# STM32H743 register map
File version: 2.4
CPU: CM7 r0p1, little endian, MPU, FPU, 4 interrupt priority bits
Registers are 32-bit, read-write, reset 0x0 unless marked. A register's access mark holds for its fields unless they carry their own. Offsets are from the block's base; [hi:lo] are bit positions; {n}, {i} and the like mark numbered series.

## SDMMC1
Base 0x52007000
Same registers: SDMMC2 0x48022400
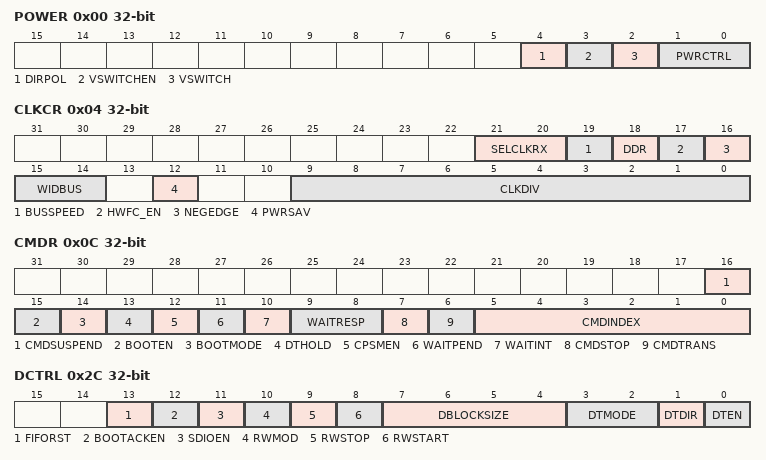
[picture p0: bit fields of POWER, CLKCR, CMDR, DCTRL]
0x00 POWER — SDMMC 电源控制寄存器
  [4] DIRPOL — 数据和命令方向信号极性选择。此位仅可在 SDMMC 处于断电状态（PWRCTRL = 00）时写入。
  [3] VSWITCHEN — 电压切换过程使能。此位仅可在 CPSM 禁用（CPSMEN = 0）时由固件写入。用于在电压切换命令响应后停止 SDMMC_CK：
  [2] VSWITCH — 电压切换序列启动。此位用于启动电压切换序列中的时序关键段：
  [1:0] PWRCTRL — SDMMC 状态控制位。这些位仅可在 SDMMC 未处于上电状态（PWRCTRL ≠ 11）时写入。用于定义 SDMMC 信号的功能状态：任何后续写入将被忽略，PWRCTRL 值将保持 11。
0x04 CLKCR — SDMMC_CLKCR 寄存器控制 SDMMC_CK 输出时钟、SDMMC_RX_CLK 接收时钟和总线宽度。
  [21:20] SELCLKRX — 接收时钟选择。这些位仅可在 CPSM 和 DPSM 均未激活（CPSMACT = 0 且 DPSMACT = 0）时写入。
  [19] BUSSPEED — 总线速度模式选择，可选 DS、HS、SDR12、SDR25、SDR50、DDR50、SDR104。此位仅可在 CPSM 和 DPSM 均未激活（CPSMACT = 0 且 DPSMACT = 0）时写入。
  [18] DDR — 数据速率信令选择。此位仅可在 CPSM 和 DPSM 均未激活（CPSMACT = 0 且 DPSMACT = 0）时写入。DDR 速率仅可在 4 位或 8 位宽总线模式（WIDBUS > 00）下选择。当 WIDBUS = 00（1 位宽总线）时，DDR = 1 无效。DDR 速率仅可在时钟分频 > 1（CLKDIV > 0）时选择。
  [17] HWFC_EN — 硬件流控使能。此位仅可在 CPSM 和 DPSM 均未激活（CPSMACT = 0 且 DPSMACT = 0）时写入。当硬件流控使能后，TXFIFOE 和 RXFIFOF 标志的含义将发生改变，请参阅第 56.8.11 节中的 SDMMC 状态寄存器定义。
  [16] NEGEDGE — SDMMC_CK 数据和命令去相位选择位。此位仅可在 CPSM 和 DPSM 均未激活（CPSMACT = 0 且 DPSMACT = 0）时写入。当时钟分频 = 1（CLKDIV = 0）时，此位无效。数据和命令在 SDMMC_CK 下降沿变化。当时钟分频 > 1（CLKDIV > 0）且 DDR = 0 时：- SDMMC_CK 边沿出现在 SDMMCCLK 上升沿。当时钟分频 > 1（CLKDIV > 0）且 DDR = 1 时：- 数据在 SDMMC_CK 边沿之后的 SDMMCCLK 下降沿变化。- SDMMC_CK 边沿出现在 SDMMCCLK 上升沿。- 数据在 SDMMC_CK 边沿之后的 SDMMC_CK 下降沿变化。- SDMMC_CK 边沿出现在 SDMMCCLK 上升沿。
  [15:14] WIDBUS — 宽总线模式使能位。此位仅可在 CPSM 和 DPSM 均未激活（CPSMACT = 0 且 DPSMACT = 0）时写入。
  [12] PWRSAV — 省电配置位。此位仅可在 CPSM 和 DPSM 均未激活（CPSMACT = 0 且 DPSMACT = 0）时写入。为节省功耗，可通过设置 PWRSAV 在总线空闲时禁用 SDMMC_CK 时钟输出：
  [9:0] CLKDIV — 时钟分频因子。此位仅可在 CPSM 和 DPSM 均未激活（CPSMACT = 0 且 DPSMACT = 0）时写入。此字段定义输入时钟（SDMMCCLK）与输出时钟（SDMMC_CK）之间的分频比：SDMMC_CK 频率 = SDMMCCLK / [2 × CLKDIV]。0xx：等等.. xxx：等等..
0x08 ARGR — SDMMC_ARGR 寄存器包含一个 32 位命令参数，作为命令消息的一部分发送给卡。
  [31:0] CMDARG — 命令参数。这些位仅可在 CPSM 禁用（CPSMEN = 0）时由固件写入。作为命令消息的一部分发送给卡的命令参数。如果命令包含参数，则必须在向命令寄存器写入命令之前将其加载到此寄存器中。
0x0C CMDR — SDMMC_CMDR 寄存器包含命令索引和命令类型位。命令索引作为命令消息的一部分发送给卡。命令类型位控制命令路径状态机（CPSM）。
  [16] CMDSUSPEND — CPSM 将该命令视为挂起或恢复命令，并发出中断周期开始/结束信号。此位仅可在 CPSM 禁用（CPSMEN = 0）时由固件写入。CMDSUSPEND = 1 且 CMDTRANS = 0：挂起命令，当响应位 BS = 0 时启动中断周期。CMDSUSPEND = 1 且 CMDTRANS = 1：带数据的恢复命令，当响应位 DF = 1 时结束中断周期。
  [15] BOOTEN — 使能引导模式过程。
  [14] BOOTMODE — 选择要使用的引导模式过程。此位仅可在 CPSM 禁用（CPSMEN = 0）时由固件写入。
  [13] DTHOLD — 在 DPSM 中暂停新数据块的发送和接收。如果此位置位，DPSM 将不会从 Wait_S 状态转移到 Send 状态，也不会从 Wait_R 状态转移到 Receive 状态。
  [12] CPSMEN — 命令路径状态机（CPSM）使能位。此位由固件写 1，当 CPSM 进入空闲状态时由硬件清零。如果此位置位，则 CPSM 使能。当 DTEN = 1 时，不会传输任何命令，也不会启动引导过程，CPSMEN 被清零为 0。
  [11] WAITPEND — CPSM 等待来自 DPSM 的数据传输结束信号（CmdPend 内部信号）。此位置位时，CPSM 在开始发送命令之前等待数据传输结束触发。WAITPEND 仅在 DTMODE = MMC 流数据传输、WIDBUS = 1 位宽总线模式、DPSMACT = 1 且 DTDIR = 主机到卡时生效。
  [10] WAITINT — CPSM 等待中断请求。如果此位置位，则 CPSM 禁用命令超时并等待卡中断请求（响应）。如果在 CPSM 等待状态下清除此位，将导致中断模式中止。
  [9:8] WAITRESP — 等待响应位。此位仅可在 CPSM 禁用（CPSMEN = 0）时由固件写入。用于配置 CPSM 是否等待响应，以及如需等待，等待何种类型的响应。
  [7] CMDSTOP — CPSM 将该命令视为停止传输命令，并向 DPSM 发送 Abort 信号。此位仅可在 CPSM 禁用（CPSMEN = 0）时由固件写入。如果此位置位，则 CPSM 在发送命令时向 DPSM 发出 Abort 信号。
  [6] CMDTRANS — CPSM 将该命令视为数据传输命令，停止中断周期，并向 DPSM 发送 DataEnable 信号。此位仅可在 CPSM 禁用（CPSMEN = 0）时由固件写入。如果此位置位，则 CPSM 在发送命令时发出中断周期结束信号，并向 DPSM 发出 DataEnable 信号。
  [5:0] CMDINDEX — 命令索引。此位仅可在 CPSM 禁用（CPSMEN = 0）时由固件写入。命令索引作为命令消息的一部分发送给卡。
0x10 RESPCMDR ro reset 0xA3C5DD01 — SDMMC 命令响应寄存器
  [5:0] RESPCMD — 响应命令索引
0x14 RESP1R ro — SDMMC_RESP1/2/3/4R 寄存器包含卡的状态信息，该状态是接收到的响应的一部分。
  [31:0] CARDSTATUS1 — 参见表 432。
{0x10+4i} RESP{i}R ro (i=2..4) — SDMMC_RESP1/2/3/4R 寄存器包含卡的状态信息，该状态是接收到的响应的一部分。
  [31:0] CARDSTATUS{i} — 参见表 404。
0x24 DTIMER — SDMMC_DTIMER 寄存器包含数据超时周期，以卡总线时钟周期为单位。一个计数器从 SDMMC_DTIMER 寄存器加载值，并在数据路径状态机（DPSM）进入 Wait_R 或 Busy 状态时开始递减。如果在 DPSM 处于上述任一状态时定时器计到 0，则超时状态标志置位。
  [31:0] DATATIME — 数据和 R1b 忙超时周期。此位仅可在 CPSM 和 DPSM 均未激活（CPSMACT = 0 且 DPSMACT = 0）时写入。以卡总线时钟周期为单位表示的数据和 R1b 忙超时周期。
0x28 DLENR — SDMMC_DLENR 寄存器包含要传输的数据字节数。该值在数据传输开始时加载到数据计数器中。
  [24:0] DATALENGTH — 数据长度值。此寄存器仅可在 DPSM 未激活（DPSMACT = 0）时由固件写入。要传输的数据字节数。当 DDR = 1 时，DATALENGTH 被截断为 2 的倍数（最后一个奇数字节不被传输）。当 DATALENGTH = 0 时，不传输任何数据；当 CPSMEN 和 CMDTRANS = 1 请求时，也不传输任何命令，DTEN 和 CPSMEN 被清零为 0。
0x2C DCTRL — SDMMC_DCTRL 寄存器控制数据路径状态机（DPSM）。
  [13] FIFORST — FIFO 复位，将清空所有剩余数据。此位仅可在 IDMAEN = 0 且 DPSM 激活（DPSMACT = 1）时由固件写入。此位仅在发生传输错误或传输暂停时生效。
  [12] BOOTACKEN — 使能引导确认的接收。此位仅可在 DPSM 未激活（DPSMACT = 0）时由固件写入。
  [11] SDIOEN — SD I/O 中断使能功能。此位仅可在 DPSM 未激活（DPSMACT = 0）时由固件写入。如果此位置位，则 DPSM 使能 SD I/O 卡特定的中断操作。
  [10] RWMOD — 读等待模式。此位仅可在 DPSM 未激活（DPSMACT = 0）时由固件写入。
  [9] RWSTOP — 读等待停止。此位由固件写入，当 DPSM 从 READ_WAIT 状态转移到 WAIT_R 或 IDLE 状态时由硬件自动清零。
  [8] RWSTART — 读等待启动。如果此位置位，读等待操作启动。
  [7:4] DBLOCKSIZE — 数据块大小。此位仅可在 DPSM 未激活（DPSMACT = 0）时由固件写入。定义选择块数据传输模式时的数据块长度：当 DATALENGTH 不是 DBLOCKSIZE 的倍数时，传输的数据在 DBLOCKSIZE 的倍数处截断（任何剩余数据将不被传输）。当 DDR = 1 时，不得使用 DBLOCKSIZE = 0000（不会传输任何数据）。
  [3:2] DTMODE — 数据传输模式选择。此位仅可在 DPSM 未激活（DPSMACT = 0）时由固件写入。
  [1] DTDIR — 数据传输方向选择。此位仅可在 DPSM 未激活（DPSMACT = 0）时由固件写入。
  [0] DTEN — 数据传输使能位。此位仅可在 DPSM 未激活（DPSMACT = 0）时由固件写入。数据传输完成时由硬件清零。此位仅应在不使用关联数据传输命令时用于传输数据，即不应与 SD 或 eMMC 卡一起使用。
0x30 DCNTR ro — 当 DPSM 从空闲状态转移到 Wait_R 或 Wait_S 状态时，SDMMC_DCNTR 寄存器从数据长度寄存器（参见 SDMMC_DLENR）加载值。随着数据传输，计数器递减该值直到达到 0。然后 DPSM 转移到空闲状态，当没有错误发生时，数据状态结束标志（DATAEND）置位。
  [24:0] DATACOUNT — 数据计数值。读取时，返回剩余待传输的数据字节数。写入无效。
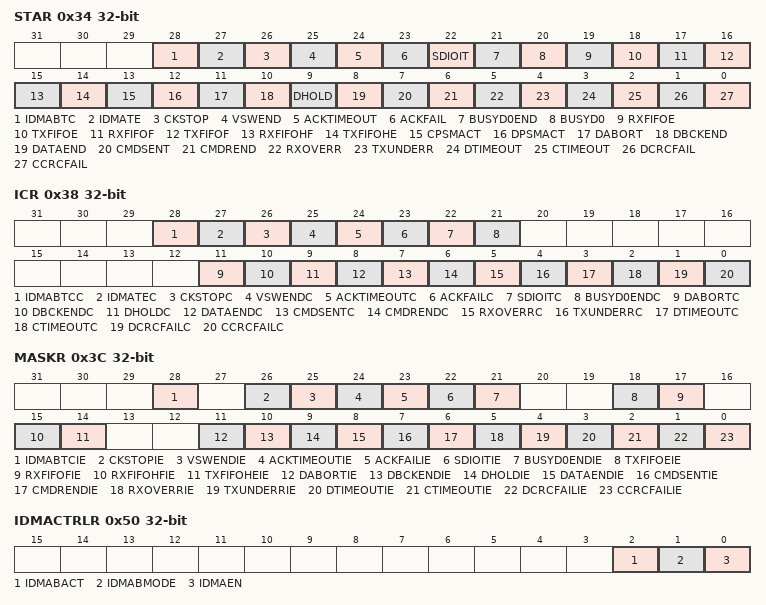
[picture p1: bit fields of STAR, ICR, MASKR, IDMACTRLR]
0x34 STAR ro — SDMMC_STAR 寄存器为只读寄存器。包含两种类型的标志：静态标志（位 [29, 21, 11:0]）：这些位保持有效状态，直到通过写入 SDMMC 中断清零寄存器（参见 SDMMC_ICR）将其清零。动态标志（位 [20:12]）：这些位根据底层逻辑的状态改变状态（例如，FIFO 满和空标志在数据写入 FIFO 时置位和清零）。
  [28] IDMABTC — IDMA 缓冲区传输完成。通过写入 SDMMC_ICR 中对应的中断清零位来清除此中断标志。
  [27] IDMATE — IDMA 传输错误。通过写入 SDMMC_ICR 中对应的中断清零位来清除此中断标志。
  [26] CKSTOP — SDMMC_CK 在电压切换过程中停止。通过写入 SDMMC_ICR 中对应的中断清零位来清除此中断标志。
  [25] VSWEND — 电压切换时序关键段完成。通过写入 SDMMC_ICR 中对应的中断清零位来清除此中断标志。
  [24] ACKTIMEOUT — 引导确认超时。通过写入 SDMMC_ICR 中对应的中断清零位来清除此中断标志。
  [23] ACKFAIL — 收到引导确认（引导确认校验失败）。通过写入 SDMMC_ICR 中对应的中断清零位来清除此中断标志。
  [22] SDIOIT — 收到 SDIO 中断。通过写入 SDMMC_ICR 中对应的中断清零位来清除此中断标志。
  [21] BUSYD0END — 检测到 CMD 响应后的 SDMMC_D0 忙结束。这仅指示 CMD 响应后的忙结束。此位不指示由数据传输引起的忙状态。通过写入 SDMMC_ICR 中对应的中断清零位来清除此中断标志。
  [20] BUSYD0 — SDMMC_D0 线（Busy）的反相值，在 CMD 响应结束时采样一次，并在 CMD 响应后 2 个 SDMMC_CK 周期再次采样。当 SDMMC_D0 线从忙变为不忙时，此位复位为不忙。此位不指示由数据传输引起的忙状态。此标志仅为硬件状态标志，不产生中断。
  [19] RXFIFOE — 接收 FIFO 空。此标志仅为硬件状态标志，不产生中断。当 FIFO 有一个位置变为满时，此位清零。
  [18] TXFIFOE — 发送 FIFO 空。当 FIFO 有一个位置变为满时，此位清零。
  [17] RXFIFOF — 接收 FIFO 满。当 FIFO 有一个位置变为空时，此位清零。
  [16] TXFIFOF — 发送 FIFO 满。此标志仅为硬件状态标志，不产生中断。当 FIFO 有一个位置变为空时，此位清零。
  [15] RXFIFOHF — 接收 FIFO 半满。FIFO 中至少有总容量一半的字数。当 FIFO 变为半空 + 1 时，此位清零。
  [14] TXFIFOHE — 发送 FIFO 半空。至少有一半容量的字可写入 FIFO。当 FIFO 变为半满 + 1 时，此位清零。
  [13] CPSMACT — 命令路径状态机激活，即不在空闲状态。此标志仅为硬件状态标志，不产生中断。
  [12] DPSMACT — 数据路径状态机激活，即不在空闲状态。此标志仅为硬件状态标志，不产生中断。
  [11] DABORT — 数据传输被 CMD12 中止。通过写入 SDMMC_ICR 中对应的中断清零位来清除此中断标志。
  [10] DBCKEND — 数据块已发送/接收（CRC 校验通过），且 DPSM 转移到 READWAIT 状态。通过写入 SDMMC_ICR 中对应的中断清零位来清除此中断标志。
  [9] DHOLD — 数据传输暂停。通过写入 SDMMC_ICR 中对应的中断清零位来清除此中断标志。
  [8] DATAEND — 数据传输正确结束（数据计数器 DATACOUNT 为零且未发生错误）。通过写入 SDMMC_ICR 中对应的中断清零位来清除此中断标志。
  [7] CMDSENT — 命令已发送（无需响应）。通过写入 SDMMC_ICR 中对应的中断清零位来清除此中断标志。
  [6] CMDREND — 收到命令响应（CRC 校验通过或无 CRC）。通过写入 SDMMC_ICR 中对应的中断清零位来清除此中断标志。
  [5] RXOVERR — 接收 FIFO 溢出错误或 IDMA 写传输错误。通过写入 SDMMC_ICR 中对应的中断清零位来清除此中断标志。
  [4] TXUNDERR — 发送 FIFO 欠载错误或 IDMA 读传输错误。通过写入 SDMMC_ICR 中对应的中断清零位来清除此中断标志。
  [3] DTIMEOUT — 数据超时。通过写入 SDMMC_ICR 中对应的中断清零位来清除此中断标志。
  [2] CTIMEOUT — 命令响应超时。通过写入 SDMMC_ICR 中对应的中断清零位来清除此中断标志。命令超时周期固定为 64 个 SDMMC_CK 时钟周期。
  [1] DCRCFAIL — 数据块已发送/接收（CRC 校验失败）。通过写入 SDMMC_ICR 中对应的中断清零位来清除此中断标志。
  [0] CCRCFAIL — 收到命令响应（CRC 校验失败）。通过写入 SDMMC_ICR 中对应的中断清零位来清除此中断标志。
0x38 ICR — SDMMC_ICR 寄存器为只写寄存器。将某位写 1 可清零 SDMMC_STAR 状态寄存器中对应的位。
  [28] IDMABTCC — IDMA 缓冲区传输完成清零位。由软件置位以清零 IDMABTC 标志。
  [27] IDMATEC — IDMA 传输错误清零位。由软件置位以清零 IDMATE 标志。
  [26] CKSTOPC — CKSTOP 标志清零位。由软件置位以清零 CKSTOP 标志。
  [25] VSWENDC — VSWEND 标志清零位。由软件置位以清零 VSWEND 标志。
  [24] ACKTIMEOUTC — ACKTIMEOUT 标志清零位。由软件置位以清零 ACKTIMEOUT 标志。
  [23] ACKFAILC — ACKFAIL 标志清零位。由软件置位以清零 ACKFAIL 标志。
  [22] SDIOITC — SDIOIT 标志清零位。由软件置位以清零 SDIOIT 标志。
  [21] BUSYD0ENDC — BUSYD0END 标志清零位。由软件置位以清零 BUSYD0END 标志。
  [11] DABORTC — DABORT 标志清零位。由软件置位以清零 DABORT 标志。
  [10] DBCKENDC — DBCKEND 标志清零位。由软件置位以清零 DBCKEND 标志。
  [9] DHOLDC — DHOLD 标志清零位。由软件置位以清零 DHOLD 标志。
  [8] DATAENDC — DATAEND 标志清零位。由软件置位以清零 DATAEND 标志。
  [7] CMDSENTC — CMDSENT 标志清零位。由软件置位以清零 CMDSENT 标志。
  [6] CMDRENDC — CMDREND 标志清零位。由软件置位以清零 CMDREND 标志。
  [5] RXOVERRC — RXOVERR 标志清零位。由软件置位以清零 RXOVERR 标志。
  [4] TXUNDERRC — TXUNDERR 标志清零位。由软件置位以清零 TXUNDERR 标志。
  [3] DTIMEOUTC — DTIMEOUT 标志清零位。由软件置位以清零 DTIMEOUT 标志。
  [2] CTIMEOUTC — CTIMEOUT 标志清零位。由软件置位以清零 CTIMEOUT 标志。
  [1] DCRCFAILC — DCRCFAIL 标志清零位。由软件置位以清零 DCRCFAIL 标志。
  [0] CCRCFAILC — CCRCFAIL 标志清零位。由软件置位以清零 CCRCFAIL 标志。
0x3C MASKR — 中断屏蔽寄存器通过将对应位置 1 来确定哪些状态标志产生中断请求。
  [28] IDMABTCIE — IDMA 缓冲区传输完成中断使能。由软件置位/清零以使能/禁用 IDMA 完成传输某个内存缓冲区的全部数据时产生的中断。
  [26] CKSTOPIE — 电压切换时钟停止中断使能。由软件置位/清零以使能/禁用由电压切换时钟停止引起的中断。
  [25] VSWENDIE — 电压切换时序关键段完成中断使能。由软件置位/清零以使能/禁用电压切换时序关键段完成时产生的中断。
  [24] ACKTIMEOUTIE — 确认超时中断使能。由软件置位/清零以使能/禁用由确认超时引起的中断。
  [23] ACKFAILIE — 确认失败中断使能。由软件置位/清零以使能/禁用由确认失败引起的中断。
  [22] SDIOITIE — SDIO 模式中断接收中断使能。由软件置位/清零以使能/禁用接收到 SDIO 模式中断时产生的中断。
  [21] BUSYD0ENDIE — BUSYD0END 中断使能。由软件置位/清零以使能/禁用在 CMD 响应后 SDMMC_D0 信号从忙变为不忙时产生的中断。
  [18] TXFIFOEIE — 发送 FIFO 空中断使能。由软件置位/清零以使能/禁用由发送 FIFO 空引起的中断。
  [17] RXFIFOFIE — 接收 FIFO 满中断使能。由软件置位/清零以使能/禁用由接收 FIFO 满引起的中断。
  [15] RXFIFOHFIE — 接收 FIFO 半满中断使能。由软件置位/清零以使能/禁用由接收 FIFO 半满引起的中断。
  [14] TXFIFOHEIE — 发送 FIFO 半空中断使能。由软件置位/清零以使能/禁用由发送 FIFO 半空引起的中断。
  [11] DABORTIE — 数据传输中止中断使能。由软件置位/清零以使能/禁用由数据传输被中止引起的中断。
  [10] DBCKENDIE — 数据块结束中断使能。由软件置位/清零以使能/禁用由数据块结束引起的中断。
  [9] DHOLDIE — 数据暂停中断使能。由软件置位/清零以使能/禁用在 DPSM Wait_S 状态下暂停发送新数据时产生的中断。
  [8] DATAENDIE — 数据结束中断使能。由软件置位/清零以使能/禁用由数据结束引起的中断。
  [7] CMDSENTIE — 命令发送中断使能。由软件置位/清零以使能/禁用由命令发送引起的中断。
  [6] CMDRENDIE — 命令响应接收中断使能。由软件置位/清零以使能/禁用由收到命令响应引起的中断。
  [5] RXOVERRIE — 接收 FIFO 溢出错误中断使能。由软件置位/清零以使能/禁用由接收 FIFO 溢出错误引起的中断。
  [4] TXUNDERRIE — 发送 FIFO 欠载错误中断使能。由软件置位/清零以使能/禁用由发送 FIFO 欠载错误引起的中断。
  [3] DTIMEOUTIE — 数据超时中断使能。由软件置位/清零以使能/禁用由数据超时引起的中断。
  [2] CTIMEOUTIE — 命令超时中断使能。由软件置位/清零以使能/禁用由命令超时引起的中断。
  [1] DCRCFAILIE — 数据 CRC 校验失败中断使能。由软件置位/清零以使能/禁用由数据 CRC 校验失败引起的中断。
  [0] CCRCFAILIE — 命令 CRC 校验失败中断使能。由软件置位/清零以使能/禁用由命令 CRC 校验失败引起的中断。
0x40 ACKTIMER — SDMMC_ACKTIMER 寄存器包含确认超时周期，以 SDMMC_CK 总线时钟周期为单位。一个计数器从 SDMMC_ACKTIMER 寄存器加载值，并在数据路径状态机（DPSM）进入 Wait_Ack 状态时开始递减。如果在 DPSM 处于此状态时定时器计到 0，则确认超时状态标志置位。
  [24:0] ACKTIME — 引导确认超时周期。此位仅可在 CPSM 禁用（CPSMEN = 0）时由固件写入。以卡总线时钟周期为单位表示的引导确认超时周期。
0x50 IDMACTRLR — 接收和发送 FIFO 可作为 32 位宽寄存器进行读写。FIFO 在 32 个连续地址上包含 32 个条目。这允许 CPU 使用其加载和存储多条指令来读写 FIFO。
  [2] IDMABACT — 双缓冲区模式激活缓冲区指示。此位仅可在 DPSM 未激活（DPSMACT = 0）时由固件写入。当 IDMA 使能时，此位由硬件翻转。
  [1] IDMABMODE — 缓冲区模式选择。此位仅可在 DPSM 未激活（DPSMACT = 0）时由固件写入。
  [0] IDMAEN — IDMA 使能。此位仅可在 DPSM 未激活（DPSMACT = 0）时由固件写入。
0x54 IDMABSIZER — SDMMC_IDMABSIZER 寄存器包含双缓冲区配置下的缓冲区大小。
  [12:5] IDMABNDT — 每缓冲区传输次数。此 8 位值乘以 8 可得到以 32 位字为单位的缓冲区大小，乘以 32 可得到以字节为单位的缓冲区大小。示例：IDMABNDT = 0x01：缓冲区大小 = 8 字 = 32 字节。这些位仅可在 DPSM 未激活（DPSMACT = 0）时由固件写入。
0x58 IDMABASE0R — SDMMC_IDMABASE0R 寄存器包含单缓冲区配置下的内存缓冲区基地址，以及双缓冲区配置下的缓冲区 0 基地址。
  [31:0] IDMABASE0 — 缓冲区 0 内存基地址位 [31:2]，应按字对齐（位 [1:0] 始终为 0 且只读）。此寄存器可在 DPSM 未激活（DPSMACT = 0）时由固件写入，也可在 DPSM 激活（DPSMACT = 1）且内存缓冲区 0 未激活（IDMABACT = 1）时由固件动态写入。
0x5C IDMABASE1R — SDMMC_IDMABASE1R 寄存器包含双缓冲区配置下第二个缓冲区的内存基地址。
  [31:0] IDMABASE1 — 缓冲区 1 内存基地址，应按字对齐（位 [1:0] 始终为 0 且只读）。此寄存器可在 DPSM 未激活（DPSMACT = 0）时由固件写入，也可在 DPSM 激活（DPSMACT = 1）且内存缓冲区 1 未激活（IDMABACT = 0）时由固件动态写入。
0x80 FIFOR — 接收和发送 FIFO 只能作为字（32 位）宽寄存器进行读写。FIFO 在连续地址上包含 16 个条目。这允许 CPU 使用其加载和存储多条指令来读写 FIFO。当以半字或字节方式访问 SDMMC_FIFOR 时，会产生 AHB 总线故障。
  [31:0] FIFODATA — 接收和发送 FIFO 数据。此寄存器仅可在 DPSM 激活（DPSMACT = 1）时由固件读写。FIFO 数据占用 16 个 32 位字条目。
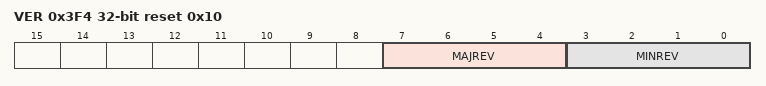
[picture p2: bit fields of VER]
0x3F4 VER ro reset 0x10 — SDMMC IP 版本寄存器
  [7:4] MAJREV — IP 主版本号。
  [3:0] MINREV — IP 次版本号。
0x3F8 ID ro reset 0x140022 — SDMMC IP 标识寄存器
  [31:0] IP_ID — SDMMC IP 标识。
